# cameraif_reva register map
Registers are 32-bit, read-write, no defined reset value unless marked. A register's access mark holds for its fields unless they carry their own. Offsets are from the block's base; lines under a group give offsets from that group; [hi:lo] are bit positions; {n}, {i} and the like mark numbered series; 'fields as' and 'values as' point back to an identical list; <NAME> marks a mode.

## Memory map
0x4000E000 CAMERAIF size 0x1000 — CameraIF Interface.

## Interrupts
91 CameraIF (CAMERAIF)

## CAMERAIF — CameraIF Interface.
Base 0x4000E000
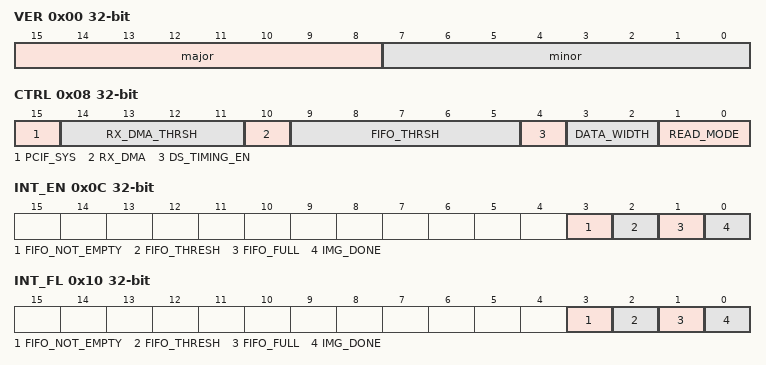
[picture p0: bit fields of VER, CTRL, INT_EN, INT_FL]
0x00 VER — CameraIF Version
  [15:8] major — Major version number
  [7:0] minor — Minor version number
0x04 FIFO_SIZE — 1-Wire Master Clock Divisor.
  [7:0] fifo_size
0x08 CTRL — Control register
  [15] PCIF_SYS — PCIF control
    0=dis (PCIF disabled.); 1=en (PCIF enabled.)
  [14:11] RX_DMA_THRSH — DMA mode threshold Level
  [10] RX_DMA — DMA mode enabled
    0=dis (DMA mode disabled.); 1=en (DMA mode enabled.)
  [9:5] FIFO_THRSH — Data FIFO threshold Setting
  [4] DS_TIMING_EN — Ds timing enabled
    0=dis (timing from VSYNC,HSYNC); 1=en (timing embedded in data using SAV EAV codes.)
  [3:2] DATA_WIDTH
    0=8bit; 1=10bit; 2=12bit
  [1:0] READ_MODE
    0=dis (Camera interface disabled); 1=single_img (single image captured); 2=Continuous image captured
0x0C INT_EN — Interrupt Enable register
  [3] FIFO_NOT_EMPTY — FIFO Threshold Level Met
  [2] FIFO_THRESH — FIFO Threshold Level Met
  [1] FIFO_FULL
  [0] IMG_DONE — Image done
0x10 INT_FL — Interrupt Flags register
  fields as INT_EN
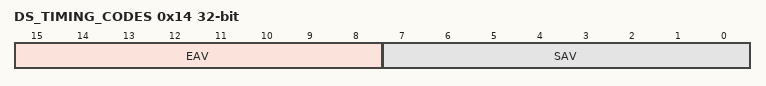
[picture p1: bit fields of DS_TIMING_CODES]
0x14 DS_TIMING_CODES
  [15:8] EAV — End active video code
  [7:0] SAV — Start active video code
0x30 FIFO_DATA
  [31:0] FIFO_DATA — Data From the fifo to be read by the dma.
